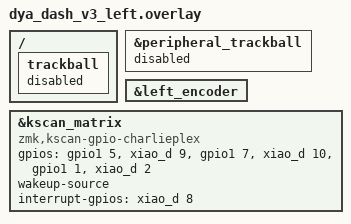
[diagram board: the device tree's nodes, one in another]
#include "dya_dash_v3.dtsi"

/ {
	trackball: trackball {
		status = "disabled";
	};
};

&peripheral_trackball {
	status = "disabled";// enabled by snippet
};

&left_encoder {
	status = "okay";
};

&kscan_matrix {
	compatible = "zmk,kscan-gpio-charlieplex";
	gpios =
	<&gpio1 5  (GPIO_ACTIVE_HIGH)>
	, <&xiao_d 9 (GPIO_ACTIVE_HIGH)>
	, <&gpio1 7  (GPIO_ACTIVE_HIGH)>
	, <&xiao_d 10 (GPIO_ACTIVE_HIGH)>
	, <&gpio1 1  (GPIO_ACTIVE_HIGH)>
	, <&xiao_d 2 (GPIO_ACTIVE_HIGH)>
	;
	wakeup-source;
	interrupt-gpios = <&xiao_d 8 (GPIO_ACTIVE_HIGH | GPIO_PULL_DOWN)>;
};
